# AC784x register map
Vendor: AutoChips; Series: AC78; File version: 1.0
CPU: CM4 r0p1, little endian, MPU, FPU, VTOR, 4 interrupt priority bits
Registers are 32-bit, read-write, reset 0x0 unless marked. A register's access mark holds for its fields unless they carry their own. Offsets are from the block's base; [hi:lo] are bit positions; {n}, {i} and the like mark numbered series; 'fields as' and 'values as' point back to an identical list.

## ACMP0 — Analog comparator
Base 0x40005000
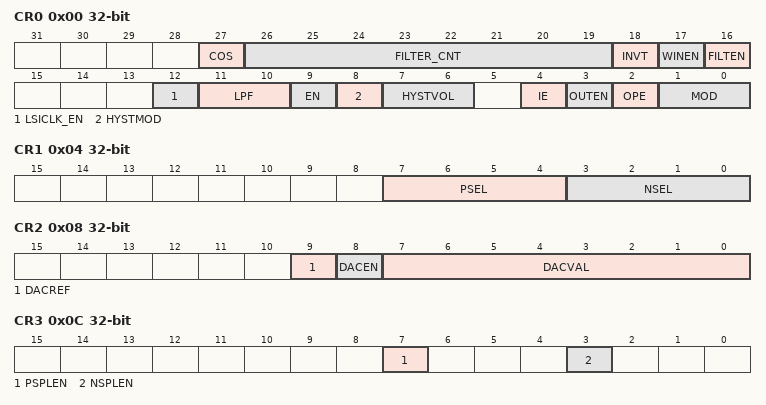
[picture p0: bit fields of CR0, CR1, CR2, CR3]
0x00 CR0 — ACMP Configuration Register 0
  [27] COS — ACMP output select
    0=set CMPO to equal COUT(filtered); 1=set CMPO to equal COUTA(unfiltered)
  [26:19] FILTER_CNT — Filter Count
  [18] INVT — Comparator invert
    0=Does not invert the comparator output; 1=Inverts the comparator output
  [17] WINEN — Windown mode Enable
    0=Windown mode is disabled; 1=Windown mode is enabled
  [16] FILTEN — Digital Filter Enable
    0=Digital Filter is disabled; 1=Digital Filter is enabled
  [12] LSICLK_EN — ACMP function clock select
    0=BUS_CLK without gate control; 1=LSI 128K clock
  [11:10] LPF — Low pass filter
    0=500KHz; 1=1MHz; 2=2MHz; 3=bypass
  [9] EN — Analog Comparator Enable
    0=ACMP is disabled; 1=ACMP is enabled
  [8] HYSTMOD — Hysteresis mode
    0=Falling edge; 1=Both edge
  [7:6] HYSTVOL — Hysteresis voltage
    0=0mV; 1=10mV; 2=20mV; 3=40mV
  [4] IE — Interrupt Enable
    0=Disable the interrupt; 1=Enable the interrupt
  [3] OUTEN — ACMP Output Enable
    0=Disable ACMP OUTPUT; 1=Enable ACMP OUTPUT
  [2] OPE — ACMP hall output Enable
    0=ACMP hall output Disabled; 1=ACMP hall output enabled
  [1:0] MOD — ACMP sensitivity modes of the interrupt trigger
    0=ACMP interrupt on output falling edge; 1=ACMP interrupt on output rising edge; 2=ACMP interrupt on output falling edge; 3=ACMP interrupt on output falling or rising edge
0x04 CR1 — ACMP Configuration Register 1
  [7:4] PSEL — ACMP Positive Input Select
    {v}=External input {v} (v=0..7); 8=DAC output
  [3:0] NSEL — ACMP Negative Input Select
    {v}=External input {v} (v=0..7); 8=DAC output
0x08 CR2 — ACMP configuration register 2
  [9] DACREF — ACMP DAC reference select
    0=DAC selects bandgap as reference; 1=DAC selects Vdd as reference
  [8] DACEN — DAC Enable
    0=The DAC is disabled; 1=The DAC is enabled
  [7:0] DACVAL — DAC Output Value
0x0C CR3 — ACMP configuration register 3
  [7] PSPLEN — ACMP positive input polling mode enable
    0=ACMP positive input polling mode disabled; 1=ACMP positive input polling mode enabled
  [3] NSPLEN — ACMP negative input polling mode enable
    0=ACMP negative input polling mode disabled; 1=ACMP negative input polling mode enabled
0x10 CR4 — ACMP configuration register 4
  [8:0] PLSEQ — ACMP polling channel sequence set
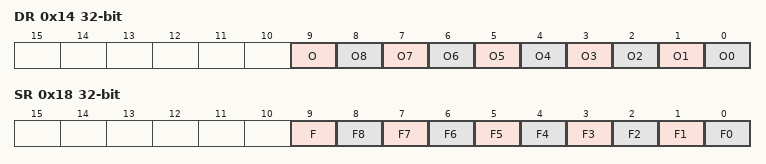
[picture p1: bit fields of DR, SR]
0x14 DR ro — ACMP data output register 0
  [9] O rw — ACMP general mode output
  [n] O{n} (n=0..8) — ACMP polling mode channel {n} output
0x18 SR — ACMP status register 0
  [9] F — ACMP general mode interrupt flag
  [n] F{n} (n=0..8) — ACMP polling mode channel {n} interrupt flag
0x1C FD — ACMP polling frequency divider register
  [1:0] PLFD — ACMP polling mode frequency divider
    0=source_clk/256; 1=source_clk/101; 2=source_clk/71; 3=source_clk/51
0x20 OPA — ACMP hall output A register
  [3:0] OPSEL — ACMP Hall output
    {v}=polling channel {v} (v=0..7); 8=polling DAC
0x24 OPB — ACMP hall output B register
  fields as OPA
0x28 OPC — ACMP hall output C register
  fields as OPA
0x48 CLK — ACMP clock register
  [2:0] PSC — Input clock prescaler
    {v}=Divide by {v+1} (v=0..7)

## PDT0 — Programmable Delay Timer
Base 0x40086000
Same registers: PDT1 0x40086800
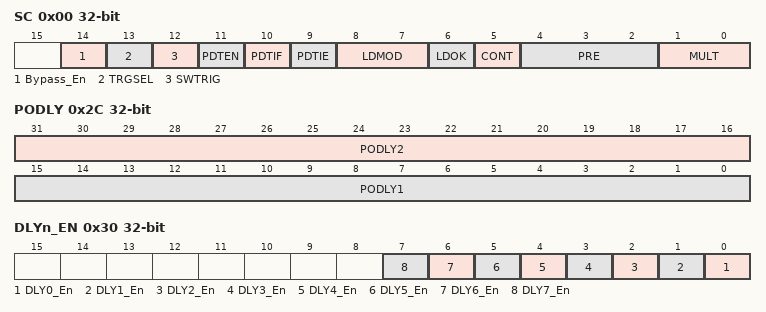
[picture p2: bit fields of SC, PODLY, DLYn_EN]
0x00 SC — PDT Config Register 1
  [14] Bypass_En — Bypass enable
    0=Delay Mode; 1=Bypass of all delay channel,output trigger immediately when receiving a trigger
  [13] TRGSEL — Trigger Input Source Select
    0=Hardware Trigger; 1=Software Trigger
  [12] SWTRIG — Software Trigger
    0=Writing 0 to SWTRIG has no effect; 1=Writing 1 to SWTRIG,Resets and restarts the counter
  [11] PDTEN — PDT Enable
    0=PDT Disable,Counter is Off; 1=PDT Enable
  [10] PDTIF — PDT Interrupt Flag
    0=Write Zero to Clear PDTIF; 1=Writing 1 to PDTIF has no effect
  [9] PDTIE — PDT Interrupt Enable
    0=PDT Interrupt disabled; 1=PDT Interrupt enabled
  [8:7] LDMOD — Load Mode Select
    0=Load After 1 is Written to LDOK; 1=Load When the PDT Counter(CNT) = MODE + 1, After 1 is Written to LDOK; 2=Load When a trigger input event is detected, After 1 is Written to LDOK; 3=Load When the PDT Counter(CNT) = MODE + 1, or a trigger input event is detected, After 1 is Written to LDOK
  [6] LDOK — Load OK
    0=Write 0 To LDOK Has No Effect; 1=Load OK
  [5] CONT — Continuous Mode Enable
    0=PDT operation In One-Shot Mode; 1=PDT operation In Continuous Mode
  [4:2] PRE — Prescaler Divider Select
    0=Counting uses the peripheral clock divided by MULT; 1=Counting uses the peripheral clock divided by 2 * MULT; 2=Counting uses the peripheral clock divided by 4 * MULT; 3=Counting uses the peripheral clock divided by 8 * MULT; 4=Counting uses the peripheral clock divided by 16 * MULT; 5=Counting uses the peripheral clock divided by 32 * MULT; 6=Counting uses the peripheral clock divided by 64 * MULT; 7=Counting uses the peripheral clock divided by 128 * MULT
  [1:0] MULT — Multiplication Factor Select For Prescaler
    0=Multiplication factor is 1; 1=Multiplication factor is 10; 2=Multiplication factor is 20; 3=Multiplication factor is 40
0x04 MOD reset 0xFFFF — PDT Config Register2
  [15:0] MOD — PDT Modulus
{0x8+4i} DLY{i} (i=0..7) — PDT Config Register{i+3}
  [15:0] DLY{i} — PDT Delay{i}
0x28 IDLY reset 0xFFFF — PDT Config Register11
  [15:0] IDLY — PDT Interrupt Delay
0x2C PODLY — PDT Config Register12
  [31:16] PODLY2 — PDT Pulse-Out Delay2
  [15:0] PODLY1 — PDT Pulse-Out Delay1
0x30 DLYn_EN — Delay Enable Register
  [n] DLY{n}_En (n=0..7) — PDT DLY{n} Trigger Enable
    0=PDT DLY{n} Disable; 1=PDT DLY{n} Enable
0x34 POEN — Pulse-Out Enable register
  [0] POEN — PDT Pulse-Out Enable
    0=PDT Pulse-Out disable; 1=PDT Pulse-Out Enable
0x38 CNT — Counter register
  [15:0] CNT ro — PDT Counter
